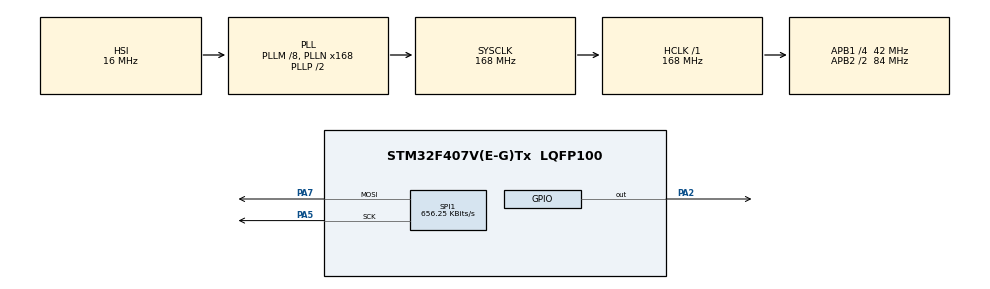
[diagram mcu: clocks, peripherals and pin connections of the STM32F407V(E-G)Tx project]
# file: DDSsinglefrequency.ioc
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Mcu.Family=STM32F4
Mcu.Name=STM32F407V(E-G)Tx
Mcu.Package=LQFP100
NVIC.PriorityGroup=NVIC_PRIORITYGROUP_4
PA13.Mode=Serial_Wire
PA13.Signal=SYS_JTMS-SWDIO
PA14.Mode=Serial_Wire
PA14.Signal=SYS_JTCK-SWCLK
PA2.Signal=GPIO_Output
PA5.Mode=TX_Only_Simplex_Unidirect_Master
PA5.Signal=SPI1_SCK
PA7.Mode=TX_Only_Simplex_Unidirect_Master
PA7.Signal=SPI1_MOSI
ProjectManager.HeapSize=0x200
ProjectManager.StackSize=0x400
ProjectManager.TargetToolchain=STM32CubeIDE
RCC.48MHZClocksFreq_Value=84000000
RCC.AHBFreq_Value=168000000
RCC.APB1CLKDivider=RCC_HCLK_DIV4
RCC.APB1Freq_Value=42000000
RCC.APB1TimFreq_Value=84000000
RCC.APB2CLKDivider=RCC_HCLK_DIV2
RCC.APB2Freq_Value=84000000
RCC.APB2TimFreq_Value=168000000
RCC.CortexFreq_Value=168000000
RCC.HCLKFreq_Value=168000000
RCC.HSE_VALUE=25000000
RCC.HSI_VALUE=16000000
RCC.LSE_VALUE=32768
RCC.PLLM=8
RCC.PLLN=168
RCC.SYSCLKFreq_VALUE=168000000
RCC.SYSCLKSource=RCC_SYSCLKSOURCE_PLLCLK
RCC.VCOOutputFreq_Value=336000000
SPI1.BaudRatePrescaler=SPI_BAUDRATEPRESCALER_128
SPI1.CalculateBaudRate=656.25 KBits/s
SPI1.Direction=SPI_DIRECTION_2LINES
SPI1.FirstBit=SPI_FIRSTBIT_LSB
SPI1.Mode=SPI_MODE_MASTER
SPI1.VirtualType=VM_MASTER
board=custom

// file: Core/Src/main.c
/* USER CODE BEGIN Header */
/**
  ******************************************************************************
  * @file           : main.c
  * @brief          : Main program body
  ******************************************************************************
  * @attention
  *
  * <h2><center>&copy; Copyright (c) 2021 STMicroelectronics.
  * All rights reserved.</center></h2>
  *
  * This software component is licensed by ST under BSD 3-Clause license,
  * the "License"; You may not use this file except in compliance with the
  * License. You may obtain a copy of the License at:
  *                        opensource.org/licenses/BSD-3-Clause
  *
  ******************************************************************************
  */
/* USER CODE END Header */
#include "main.h"

/* USER CODE BEGIN Includes */
#include <stdio.h>
#include <stdlib.h>
#include <math.h>

#include <stdint.h>
float Frequency={1000};
/* USER CODE END Includes */

SPI_HandleTypeDef hspi1;

void SystemClock_Config(void);
static void MX_GPIO_Init(void);
static void MX_SPI1_Init(void);

int main(void)
{

  /* MCU Configuration--------------------------------------------------------*/

  /* Reset of all peripherals, Initializes the Flash interface and the Systick. */
  HAL_Init();

  /* Configure the system clock */
  SystemClock_Config();

  /* Initialize all configured peripherals */
  MX_GPIO_Init();
  MX_SPI1_Init();
  /* USER CODE BEGIN 2 */
  HAL_GPIO_WritePin(GPIOA, GPIO_PIN_2, GPIO_PIN_SET);
  		HAL_Delay(5);
  		HAL_GPIO_WritePin(GPIOA, GPIO_PIN_2, GPIO_PIN_RESET);
  		HAL_Delay(5);
  	uint8_t SPISendData[5] = {0};
  	int32_t Freq = Frequency * (4294967296.0 / 125.0e6);

  	for (int i=0; i<4; i++, Freq>>=8)
  	{
  		SPISendData[i] = Freq & 0xFF;
  	}

  	SPISendData[4] = 0x00;

  	HAL_SPI_Transmit(&hspi1, SPISendData, 5, 50);

  	HAL_GPIO_WritePin(GPIOA, GPIO_PIN_2, GPIO_PIN_SET);
  	HAL_Delay(5);
  	HAL_GPIO_WritePin(GPIOA, GPIO_PIN_2, GPIO_PIN_RESET);
  	HAL_Delay(5);
  /* USER CODE END 2 */

  /* Infinite loop */
  while (1)
  {

  }
}

void SystemClock_Config(void)
{
  RCC_OscInitTypeDef RCC_OscInitStruct = {0};
  RCC_ClkInitTypeDef RCC_ClkInitStruct = {0};

  /** Configure the main internal regulator output voltage
  */
  __HAL_RCC_PWR_CLK_ENABLE();
  __HAL_PWR_VOLTAGESCALING_CONFIG(PWR_REGULATOR_VOLTAGE_SCALE1);
  /** Initializes the RCC Oscillators according to the specified parameters
  * in the RCC_OscInitTypeDef structure.
  */
  RCC_OscInitStruct.OscillatorType = RCC_OSCILLATORTYPE_HSI;
  RCC_OscInitStruct.HSIState = RCC_HSI_ON;
  RCC_OscInitStruct.HSICalibrationValue = RCC_HSICALIBRATION_DEFAULT;
  RCC_OscInitStruct.PLL.PLLState = RCC_PLL_ON;
  RCC_OscInitStruct.PLL.PLLSource = RCC_PLLSOURCE_HSI;
  RCC_OscInitStruct.PLL.PLLM = 8;
  RCC_OscInitStruct.PLL.PLLN = 168;
  RCC_OscInitStruct.PLL.PLLP = RCC_PLLP_DIV2;
  RCC_OscInitStruct.PLL.PLLQ = 4;
  if (HAL_RCC_OscConfig(&RCC_OscInitStruct) != HAL_OK)
  {
    Error_Handler();
  }
  /** Initializes the CPU, AHB and APB buses clocks
  */
  RCC_ClkInitStruct.ClockType = RCC_CLOCKTYPE_HCLK|RCC_CLOCKTYPE_SYSCLK
                              |RCC_CLOCKTYPE_PCLK1|RCC_CLOCKTYPE_PCLK2;
  RCC_ClkInitStruct.SYSCLKSource = RCC_SYSCLKSOURCE_PLLCLK;
  RCC_ClkInitStruct.AHBCLKDivider = RCC_SYSCLK_DIV1;
  RCC_ClkInitStruct.APB1CLKDivider = RCC_HCLK_DIV4;
  RCC_ClkInitStruct.APB2CLKDivider = RCC_HCLK_DIV2;

  if (HAL_RCC_ClockConfig(&RCC_ClkInitStruct, FLASH_LATENCY_5) != HAL_OK)
  {
    Error_Handler();
  }
}

static void MX_SPI1_Init(void)
{

  /* SPI1 parameter configuration*/
  hspi1.Instance = SPI1;
  hspi1.Init.Mode = SPI_MODE_MASTER;
  hspi1.Init.Direction = SPI_DIRECTION_2LINES;
  hspi1.Init.DataSize = SPI_DATASIZE_8BIT;
  hspi1.Init.CLKPolarity = SPI_POLARITY_LOW;
  hspi1.Init.CLKPhase = SPI_PHASE_1EDGE;
  hspi1.Init.NSS = SPI_NSS_SOFT;
  hspi1.Init.BaudRatePrescaler = SPI_BAUDRATEPRESCALER_128;
  hspi1.Init.FirstBit = SPI_FIRSTBIT_LSB;
  hspi1.Init.TIMode = SPI_TIMODE_DISABLE;
  hspi1.Init.CRCCalculation = SPI_CRCCALCULATION_DISABLE;
  hspi1.Init.CRCPolynomial = 10;
  if (HAL_SPI_Init(&hspi1) != HAL_OK)
  {
    Error_Handler();
  }

}

static void MX_GPIO_Init(void)
{
  GPIO_InitTypeDef GPIO_InitStruct = {0};

  /* GPIO Ports Clock Enable */
  __HAL_RCC_GPIOA_CLK_ENABLE();

  /*Configure GPIO pin Output Level */
  HAL_GPIO_WritePin(GPIOA, GPIO_PIN_2, GPIO_PIN_RESET);

  /*Configure GPIO pin : PA2 */
  GPIO_InitStruct.Pin = GPIO_PIN_2;
  GPIO_InitStruct.Mode = GPIO_MODE_OUTPUT_PP;
  GPIO_InitStruct.Pull = GPIO_NOPULL;
  GPIO_InitStruct.Speed = GPIO_SPEED_FREQ_LOW;
  HAL_GPIO_Init(GPIOA, &GPIO_InitStruct);

}

void Error_Handler(void)
{
  __disable_irq();
  while (1)
  {
  }
}

/************************ (C) COPYRIGHT STMicroelectronics *****END OF FILE****/
